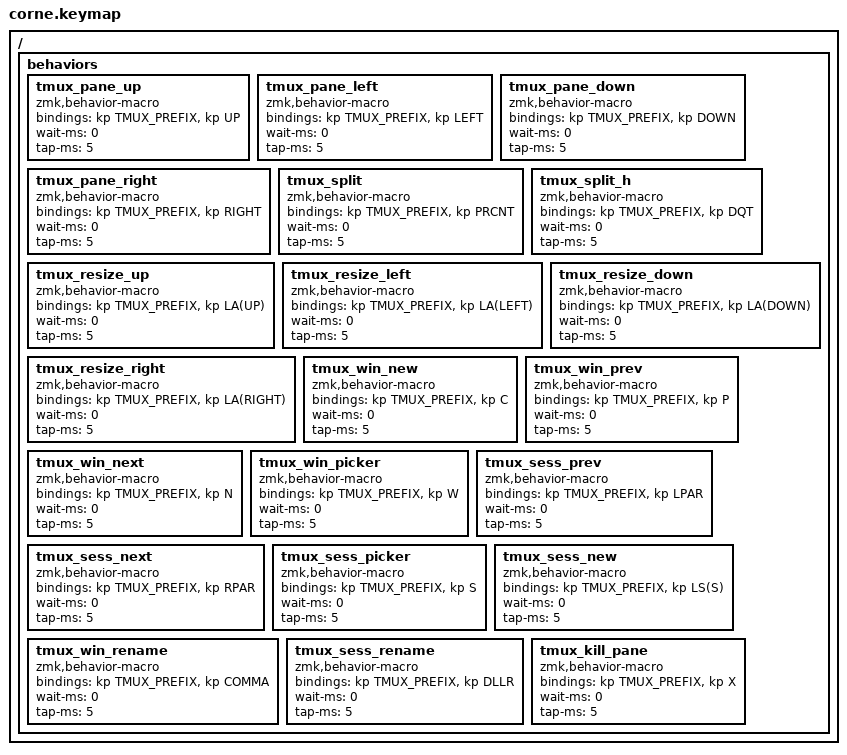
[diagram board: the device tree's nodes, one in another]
// corne.keymap - Personal layout using urob's infrastructure
// HYPER(keycode): Sends Ctrl+Shift+Alt+GUI + keycode ("Hyper" modifier combo, system-wide unique hotkey)
#define HYPER(keycode) &kp LC(LS(LA(LG(keycode))))

// Key position macros for combos (42-key layout)
#include "zmk-helpers/key-labels/42.h"

// NOTE: ZMK Studio requires a physical layout with `keys` property for visualization.
// The Corne's physical layout is defined in zmk/app/boards/shields/corne/corne.dtsi
// as `foostan_corne_6col_layout` with full `keys` property (key positions, sizes, etc.)
// The chosen node in that file sets: zmk,physical-layout = &foostan_corne_6col_layout;

// Intercept urob's ZMK_BASE_LAYER - define as no-op BEFORE including base.keymap
#define ZMK_BASE_LAYER(name, ...)

// Include urob's base.keymap (HRMs, combos, shortcuts, etc.)
#define CONFIG_WIRELESS
#include "hrm.dtsi"
#include "base.keymap"

// Tmux navigation macros - Z (held) activates the MACRO layer silently; it emits NOTHING
// by itself. Only tapping one of these action keys while Z is held fires the macro below:
// each one taps tmux's prefix (Ctrl-b), releases it, then taps the follow-up key in one
// atomic sequence - Ctrl-b is never left "armed" on its own. Portable by construction:
// these are real keystrokes, so they work in any terminal/OS tmux runs in (macOS, Linux,
// SSH) using tmux's own default prefix+arrow (select-pane) and prefix+% (split-window -h)
// bindings - no tmux.conf changes required.
#define TMUX_PREFIX LC(B)

ZMK_MACRO(tmux_pane_up,    bindings = <&kp TMUX_PREFIX &kp UP>;    wait-ms = <0>; tap-ms = <5>;)
ZMK_MACRO(tmux_pane_left,  bindings = <&kp TMUX_PREFIX &kp LEFT>;  wait-ms = <0>; tap-ms = <5>;)
ZMK_MACRO(tmux_pane_down,  bindings = <&kp TMUX_PREFIX &kp DOWN>;  wait-ms = <0>; tap-ms = <5>;)
ZMK_MACRO(tmux_pane_right, bindings = <&kp TMUX_PREFIX &kp RIGHT>; wait-ms = <0>; tap-ms = <5>;)
ZMK_MACRO(tmux_split,      bindings = <&kp TMUX_PREFIX &kp PRCNT>; wait-ms = <0>; tap-ms = <5>;)
ZMK_MACRO(tmux_split_h,    bindings = <&kp TMUX_PREFIX &kp DQT>;   wait-ms = <0>; tap-ms = <5>;)

// Pane resizing (IJKL - mirrors ESDF's inverted-T shape on the right hand)
ZMK_MACRO(tmux_resize_up,    bindings = <&kp TMUX_PREFIX &kp LA(UP)>;    wait-ms = <0>; tap-ms = <5>;)
ZMK_MACRO(tmux_resize_left,  bindings = <&kp TMUX_PREFIX &kp LA(LEFT)>;  wait-ms = <0>; tap-ms = <5>;)
ZMK_MACRO(tmux_resize_down,  bindings = <&kp TMUX_PREFIX &kp LA(DOWN)>;  wait-ms = <0>; tap-ms = <5>;)
ZMK_MACRO(tmux_resize_right, bindings = <&kp TMUX_PREFIX &kp LA(RIGHT)>; wait-ms = <0>; tap-ms = <5>;)

// Window switching
ZMK_MACRO(tmux_win_new,    bindings = <&kp TMUX_PREFIX &kp C>; wait-ms = <0>; tap-ms = <5>;)
ZMK_MACRO(tmux_win_prev,   bindings = <&kp TMUX_PREFIX &kp P>; wait-ms = <0>; tap-ms = <5>;)
ZMK_MACRO(tmux_win_next,   bindings = <&kp TMUX_PREFIX &kp N>; wait-ms = <0>; tap-ms = <5>;)
ZMK_MACRO(tmux_win_picker, bindings = <&kp TMUX_PREFIX &kp W>; wait-ms = <0>; tap-ms = <5>;)

// Session switching
ZMK_MACRO(tmux_sess_prev,   bindings = <&kp TMUX_PREFIX &kp LPAR>;  wait-ms = <0>; tap-ms = <5>;)
ZMK_MACRO(tmux_sess_next,   bindings = <&kp TMUX_PREFIX &kp RPAR>;  wait-ms = <0>; tap-ms = <5>;)
ZMK_MACRO(tmux_sess_picker, bindings = <&kp TMUX_PREFIX &kp S>;     wait-ms = <0>; tap-ms = <5>;)
ZMK_MACRO(tmux_sess_new,    bindings = <&kp TMUX_PREFIX &kp LS(S)>; wait-ms = <0>; tap-ms = <5>;)

// Renaming
ZMK_MACRO(tmux_win_rename,  bindings = <&kp TMUX_PREFIX &kp COMMA>;  wait-ms = <0>; tap-ms = <5>;)
ZMK_MACRO(tmux_sess_rename, bindings = <&kp TMUX_PREFIX &kp DLLR>;   wait-ms = <0>; tap-ms = <5>;)

// Kill pane (tmux's own y/n confirmation prompt still applies - not a one-shot destructive action)
ZMK_MACRO(tmux_kill_pane, bindings = <&kp TMUX_PREFIX &kp X>; wait-ms = <0>; tap-ms = <5>;)

// Personal layer macro - same signature as urob's ZMK_BASE_LAYER
#define PERSONAL_LAYER(name, LT, RT, LM, RM, LB, RB, LH, RH) \
    ZMK_LAYER(name, LT RT LM RM LB RB LH RH)

// ------ Personal Layers ------
#define BASE 0
#define NAV 1
#define NUM 2
#define SYM 3
#define MACRO 4
#define BLUE 5

PERSONAL_LAYER(base, 
// ╭─────────────┬─────────────┬─────────────┬─────────────┬─────────────┬─────────────╮ ╭─────────────┬─────────────┬─────────────┬─────────────┬─────────────┬─────────────╮
       &gresc         &kp Q         &kp W         &kp E         &kp R         &kp T     ,    &kp Y         &kp U         &kp I         &kp O         &kp P      &kp BACKSLASH    ,
// ├─────────────┼─────────────┼─────────────┼─────────────┼─────────────┼─────────────┤ ├─────────────┼─────────────┼─────────────┼─────────────┼─────────────┼─────────────┤
       &kp TAB     &hml LCTRL A   &hml LALT S   &hml LSHFT D  &hml LGUI F     &kp G     ,   &kp H       &hmr LGUI J   &hmr RSHFT K  &hmr LALT L   &hmr LCTRL SEMI    &kp SQT     ,
// ├─────────────┼─────────────┼─────────────┼─────────────┼─────────────┼─────────────┤ ├─────────────┼─────────────┼─────────────┼─────────────┼─────────────┼─────────────┤
       &kp DEL     &lt MACRO Z      &kp X         &kp C         &kp V         &kp B     ,   &kp N        &kp M      &kp COMMA   &kp DOT    &kp SLASH    &kp DEL        ,
// ╰─────────────┼─────────────┴─────────────┼─────────────┼─────────────┼─────────────┤ ├─────────────┼─────────────┼─────────────┼─────────────┴─────────────┴─────────────╯
                                              &kp RET  &lt NAV SPACE  &lt NUM BSPC , &kp K_APP  &lt BLUE RET &kp SPACE
//                                           ╰─────────────┴─────────────┴─────────────╯ ╰─────────────┴─────────────┴─────────────╯
)

//NAV
PERSONAL_LAYER(nav,
    
// ╭─────────────┬─────────────┬─────────────┬─────────────┬─────────────┬─────────────╮ ╭─────────────┬─────────────┬─────────────┬─────────────┬─────────────┬─────────────╮
         XXX          XXX           XXX           &kp UP         XXX           XXX      ,      XXX        &mkp MB4      &kp PG_UP     &mkp MB5      &kp C_VOL_UP  &kp C_VOL_DN    ,
// ├─────────────┼─────────────┼─────────────┼─────────────┼─────────────┼─────────────┤ ├─────────────┼─────────────┼─────────────┼─────────────┼─────────────┼─────────────┤
         XXX          XXX      &kp LEFT       &kp DOWN     &kp RIGHT       XXX      ,      XXX         &kp HOME     &kp PG_DN      &kp END         XXX          &kp C_PP     ,
// ├─────────────┼─────────────┼─────────────┼─────────────┼─────────────┼─────────────┤ ├─────────────┼─────────────┼─────────────┼─────────────┼─────────────┼─────────────┤
        &kp LCTRL          &kp LSHFT        XXX           XXX           XXX          XXX      ,      XXX           XXX           XXX           XXX           XXX           XXX         ,
// ╰─────────────┼─────────────┴─────────────┼─────────────┼─────────────┼─────────────┤ ├─────────────┼─────────────┼─────────────┼─────────────┴─────────────┴─────────────╯
                                                XXX             XXX         &mo SYM      ,      XXX           XXX           XXX
//                                           ╰─────────────┴─────────────┴─────────────╯ ╰─────────────┴─────────────┴─────────────╯
)

//NUMBERS
PERSONAL_LAYER(Num,
// ╭─────────────┬─────────────┬─────────────┬─────────────┬─────────────┬─────────────╮ ╭─────────────┬─────────────┬─────────────┬─────────────┬─────────────┬─────────────╮
         XXX          XXX          &kp N7         &kp N8         &kp N9      &kp MINUS  ,     XXX           XXX           XXX           XXX           XXX           XXX             ,
// ├─────────────┼─────────────┼─────────────┼─────────────┼─────────────┼─────────────┤ ├─────────────┼─────────────┼─────────────┼─────────────┼─────────────┼─────────────┤
         XXX         &kp N0        &kp N4         &kp N5         &kp N6      &kp EQUAL   ,     XXX           XXX           XXX           XXX           XXX           XXX             ,
// ├─────────────┼─────────────┼─────────────┼─────────────┼─────────────┼─────────────┤ ├─────────────┼─────────────┼─────────────┼─────────────┼─────────────┼─────────────┤
     &kp LCTRL   &kp LSHFT          &kp N1        &kp N2         &kp N3     XXX         ,     XXX           XXX           XXX           XXX           XXX           XXX             ,
// ╰─────────────┼─────────────┴─────────────┼─────────────┼─────────────┼─────────────┤ ├─────────────┼─────────────┼─────────────┼─────────────┴─────────────┴─────────────╯
                                                  XXX          &mo SYM    XXX                  ,    XXX           XXX           XXX
//                                           ╰─────────────┴─────────────┴─────────────╯ ╰─────────────┴─────────────┴─────────────╯
)   

PERSONAL_LAYER(Sym,
// ╭─────────────┬─────────────┬─────────────┬─────────────┬─────────────┬─────────────╮ ╭─────────────┬─────────────┬─────────────┬─────────────┬─────────────┬─────────────╮
         &kp S        XXX           XXX           XXX           XXX            XXX      ,     XXX           XXX           XXX           XXX           XXX           XXX             ,
// ├─────────────┼─────────────┼─────────────┼─────────────┼─────────────┼─────────────┤ ├─────────────┼─────────────┼─────────────┼─────────────┼─────────────┼─────────────┤
         XXX          XXX           XXX           XXX           XXX            XXX      ,     XXX           XXX           XXX           XXX           XXX           XXX             ,
// ├─────────────┼─────────────┼─────────────┼─────────────┼─────────────┼─────────────┤ ├─────────────┼─────────────┼─────────────┼─────────────┼─────────────┼─────────────┤
         XXX          XXX           XXX           XXX           XXX            XXX      ,     XXX           XXX           XXX           XXX           XXX           XXX             ,
// ╰─────────────┼─────────────┴─────────────┼─────────────┼─────────────┼─────────────┤ ├─────────────┼─────────────┼─────────────┼─────────────┴─────────────┴─────────────╯
                                                  XXX           XXX            XXX      ,     XXX       XXX           XXX
//                                           ╰─────────────┴─────────────┴─────────────╯ ╰─────────────┴─────────────┴─────────────╯
)

PERSONAL_LAYER(Macro,
// ╭─────────────┬─────────────┬─────────────┬─────────────┬─────────────┬─────────────╮ ╭─────────────┬─────────────┬─────────────┬─────────────┬─────────────┬─────────────╮
          &kp M       XXX           &kp F20       &tmux_pane_up &tmux_split     &tmux_split_h      ,     &tmux_sess_new &tmux_sess_prev &tmux_resize_up &tmux_sess_next &tmux_sess_picker XXX             ,
// ├─────────────┼─────────────┼─────────────┼─────────────┼─────────────┼─────────────┤ ├─────────────┼─────────────┼─────────────┼─────────────┼─────────────┼─────────────┤
         XXX          XXX           &tmux_pane_left &tmux_pane_down &tmux_pane_right XXX      ,     HYPER(2)      &tmux_resize_left &tmux_resize_down &tmux_resize_right &tmux_win_rename &tmux_sess_rename             ,
// ├─────────────┼─────────────┼─────────────┼─────────────┼─────────────┼─────────────┤ ├─────────────┼─────────────┼─────────────┼─────────────┼─────────────┼─────────────┤
         XXX           XXX          &kp F13       &kp F14       &kp F15        XXX      ,     HYPER(Q)      &tmux_win_new &tmux_win_prev &tmux_win_next &tmux_win_picker &tmux_kill_pane             ,
// ╰─────────────┼─────────────┴─────────────┼─────────────┼─────────────┼─────────────┤ ├─────────────┼─────────────┼─────────────┼─────────────┴─────────────┴─────────────╯
                                                  XXX           XXX            XXX      ,     XXX           XXX           XXX
//                                           ╰─────────────┴─────────────┴─────────────╯ ╰─────────────┴─────────────┴─────────────╯
)

//BLUE
PERSONAL_LAYER(Blue,
// ╭─────────────┬─────────────┬─────────────┬─────────────┬─────────────┬─────────────╮ ╭─────────────┬─────────────┬─────────────┬─────────────┬─────────────┬─────────────╮
        &kp B     &bt BT_CLR          XXX         XXX         XXX           XXX         ,     XXX           XXX          XXX              XXX         XXX       &studio_unlock             ,
// ├─────────────┼─────────────┼─────────────┼─────────────┼─────────────┼─────────────┤ ├─────────────┼─────────────┼─────────────┼─────────────┼─────────────┼─────────────┤
         XXX           XXX       &bt BT_SEL 3     XXX           XXX       &bootloader  ,  &bootloader       XXX           XXX           XXX            XXX           XXX             ,
// ├─────────────┼─────────────┼─────────────┼─────────────┼─────────────┼─────────────┤ ├─────────────┼─────────────┼─────────────┼─────────────┼─────────────┼─────────────┤
        XXX          XXX        &bt BT_SEL 0 &bt BT_SEL 1 &bt BT_SEL 2     &sys_reset  ,   &sys_reset      XXX           XXX           XXX           XXX           XXX             ,
// ╰─────────────┼─────────────┴─────────────┼─────────────┼─────────────┼─────────────┤ ├─────────────┼─────────────┼─────────────┼─────────────┴─────────────┴─────────────╯
                                                  XXX           XXX            XXX      ,     XXX           XXX           XXX
//                                           ╰─────────────┴─────────────┴─────────────╯ ╰─────────────┴─────────────┴─────────────╯
)

















// Example Hyper mapping usage:
//  HYPER(1): Ctrl+Shift+Alt+GUI+1
//  HYPER(2): Ctrl+Shift+Alt+GUI+2
//  HYPER(Q): Ctrl+Shift+Alt+GUI+Q
// For other keys, use as HYPER(<KEYCODE>)

// PERSONAL_LAYER(blue,
    
// // ╭─────────────┬─────────────┬─────────────┬─────────────┬─────────────┬─────────────╮ ╭─────────────┬─────────────┬─────────────┬─────────────┬─────────────┬─────────────╮
//          XXX          XXX           XXX           XXX           XXX            XXX      ,     XXX           XXX           XXX           XXX           XXX           XXX             ,
// // ├─────────────┼─────────────┼─────────────┼─────────────┼─────────────┼─────────────┤ ├─────────────┼─────────────┼─────────────┼─────────────┼─────────────┼─────────────┤
//          XXX          XXX           XXX           XXX           XXX            XXX      ,     XXX           XXX           XXX           XXX           XXX           XXX             ,
// // ├─────────────┼─────────────┼─────────────┼─────────────┼─────────────┼─────────────┤ ├─────────────┼─────────────┼─────────────┼─────────────┼─────────────┼─────────────┤
//          XXX          XXX           XXX           XXX           XXX            XXX      ,     XXX           XXX           XXX           XXX           XXX           XXX             ,
// // ╰─────────────┼─────────────┴─────────────┼─────────────┼─────────────┼─────────────┤ ├─────────────┼─────────────┼─────────────┼─────────────┴─────────────┴─────────────╯
//                                                   XXX           ___            XXX      ,     XXX           XXX           XXX
// //                                           ╰─────────────┴─────────────┴─────────────╯ ╰─────────────┴─────────────┴─────────────╯

// )
 
